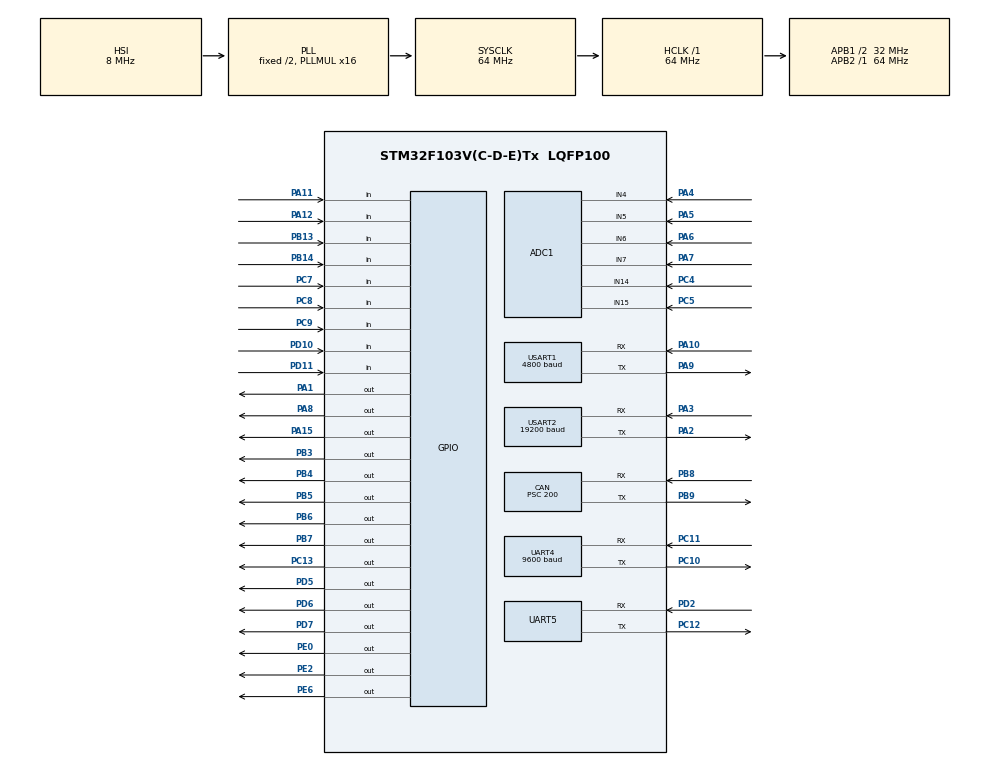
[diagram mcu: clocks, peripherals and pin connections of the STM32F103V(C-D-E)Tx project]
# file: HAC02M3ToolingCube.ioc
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ADC1.Channel-0\#ChannelRegularConversion=ADC_CHANNEL_4
ADC1.Channel-1\#ChannelRegularConversion=ADC_CHANNEL_5
ADC1.Channel-2\#ChannelRegularConversion=ADC_CHANNEL_6
ADC1.Channel-3\#ChannelRegularConversion=ADC_CHANNEL_7
ADC1.Channel-4\#ChannelRegularConversion=ADC_CHANNEL_14
ADC1.Channel-5\#ChannelRegularConversion=ADC_CHANNEL_15
ADC1.ContinuousConvMode=ENABLE
ADC1.NbrOfConversion=6
ADC1.NbrOfConversionFlag=1
ADC1.Rank-0\#ChannelRegularConversion=1
ADC1.Rank-1\#ChannelRegularConversion=2
ADC1.Rank-2\#ChannelRegularConversion=3
ADC1.Rank-3\#ChannelRegularConversion=4
ADC1.Rank-4\#ChannelRegularConversion=5
ADC1.Rank-5\#ChannelRegularConversion=6
ADC1.SamplingTime-0\#ChannelRegularConversion=ADC_SAMPLETIME_239CYCLES_5
ADC1.SamplingTime-1\#ChannelRegularConversion=ADC_SAMPLETIME_239CYCLES_5
ADC1.SamplingTime-2\#ChannelRegularConversion=ADC_SAMPLETIME_239CYCLES_5
ADC1.SamplingTime-3\#ChannelRegularConversion=ADC_SAMPLETIME_239CYCLES_5
ADC1.SamplingTime-4\#ChannelRegularConversion=ADC_SAMPLETIME_239CYCLES_5
ADC1.SamplingTime-5\#ChannelRegularConversion=ADC_SAMPLETIME_239CYCLES_5
ADC1.master=1
CAN.ABOM=DISABLE
CAN.BS1=CAN_BS1_3TQ
CAN.BS2=CAN_BS2_4TQ
CAN.CalculateBaudRate=20000
CAN.CalculateTimeBit=50000
CAN.CalculateTimeQuantum=6250.0
CAN.Prescaler=200
CAN.TTCM=DISABLE
CAN.TXFP=DISABLE
Dma.ADC1.0.Direction=DMA_PERIPH_TO_MEMORY
Dma.ADC1.0.Instance=DMA1_Channel1
Dma.ADC1.0.MemDataAlignment=DMA_MDATAALIGN_HALFWORD
Dma.ADC1.0.MemInc=DMA_MINC_ENABLE
Dma.ADC1.0.Mode=DMA_CIRCULAR
Dma.ADC1.0.PeriphDataAlignment=DMA_PDATAALIGN_HALFWORD
Dma.ADC1.0.PeriphInc=DMA_PINC_DISABLE
Dma.ADC1.0.Priority=DMA_PRIORITY_LOW
Dma.Request0=ADC1
Dma.Request1=USART1_RX
Dma.Request2=USART1_TX
Dma.Request3=USART2_RX
Dma.Request4=USART2_TX
Dma.Request5=UART4_RX
Dma.Request6=UART4_TX
Dma.UART4_RX.5.Direction=DMA_PERIPH_TO_MEMORY
Dma.UART4_RX.5.Instance=DMA2_Channel3
Dma.UART4_RX.5.MemDataAlignment=DMA_MDATAALIGN_BYTE
Dma.UART4_RX.5.MemInc=DMA_MINC_ENABLE
Dma.UART4_RX.5.Mode=DMA_NORMAL
Dma.UART4_RX.5.PeriphDataAlignment=DMA_PDATAALIGN_BYTE
Dma.UART4_RX.5.PeriphInc=DMA_PINC_DISABLE
Dma.UART4_RX.5.Priority=DMA_PRIORITY_LOW
Dma.UART4_TX.6.Direction=DMA_MEMORY_TO_PERIPH
Dma.UART4_TX.6.Instance=DMA2_Channel5
Dma.UART4_TX.6.MemDataAlignment=DMA_MDATAALIGN_BYTE
Dma.UART4_TX.6.MemInc=DMA_MINC_ENABLE
Dma.UART4_TX.6.Mode=DMA_NORMAL
Dma.UART4_TX.6.PeriphDataAlignment=DMA_PDATAALIGN_BYTE
Dma.UART4_TX.6.PeriphInc=DMA_PINC_DISABLE
Dma.UART4_TX.6.Priority=DMA_PRIORITY_LOW
Dma.USART1_RX.1.Direction=DMA_PERIPH_TO_MEMORY
Dma.USART1_RX.1.Instance=DMA1_Channel5
Dma.USART1_RX.1.MemDataAlignment=DMA_MDATAALIGN_BYTE
Dma.USART1_RX.1.MemInc=DMA_MINC_ENABLE
Dma.USART1_RX.1.Mode=DMA_NORMAL
Dma.USART1_RX.1.PeriphDataAlignment=DMA_PDATAALIGN_BYTE
Dma.USART1_RX.1.PeriphInc=DMA_PINC_DISABLE
Dma.USART1_RX.1.Priority=DMA_PRIORITY_LOW
Dma.USART1_TX.2.Direction=DMA_MEMORY_TO_PERIPH
Dma.USART1_TX.2.Instance=DMA1_Channel4
Dma.USART1_TX.2.MemDataAlignment=DMA_MDATAALIGN_BYTE
Dma.USART1_TX.2.MemInc=DMA_MINC_ENABLE
Dma.USART1_TX.2.Mode=DMA_NORMAL
Dma.USART1_TX.2.PeriphDataAlignment=DMA_PDATAALIGN_BYTE
Dma.USART1_TX.2.PeriphInc=DMA_PINC_DISABLE
Dma.USART1_TX.2.Priority=DMA_PRIORITY_LOW
Dma.USART2_RX.3.Direction=DMA_PERIPH_TO_MEMORY
Dma.USART2_RX.3.Instance=DMA1_Channel6
Dma.USART2_RX.3.MemDataAlignment=DMA_MDATAALIGN_BYTE
Dma.USART2_RX.3.MemInc=DMA_MINC_ENABLE
Dma.USART2_RX.3.Mode=DMA_NORMAL
Dma.USART2_RX.3.PeriphDataAlignment=DMA_PDATAALIGN_BYTE
Dma.USART2_RX.3.PeriphInc=DMA_PINC_DISABLE
Dma.USART2_RX.3.Priority=DMA_PRIORITY_LOW
Dma.USART2_TX.4.Direction=DMA_MEMORY_TO_PERIPH
Dma.USART2_TX.4.Instance=DMA1_Channel7
Dma.USART2_TX.4.MemDataAlignment=DMA_MDATAALIGN_BYTE
Dma.USART2_TX.4.MemInc=DMA_MINC_ENABLE
Dma.USART2_TX.4.Mode=DMA_NORMAL
Dma.USART2_TX.4.PeriphDataAlignment=DMA_PDATAALIGN_BYTE
Dma.USART2_TX.4.PeriphInc=DMA_PINC_DISABLE
Dma.USART2_TX.4.Priority=DMA_PRIORITY_LOW
IWDG.Prescaler=IWDG_PRESCALER_128
IWDG.Reload=800
Mcu.Family=STM32F1
Mcu.Name=STM32F103V(C-D-E)Tx
Mcu.Package=LQFP100
NVIC.DMA1_Channel1_IRQn=true\:0\:0\:false\:false\:true\:false\:true\:true
NVIC.DMA1_Channel4_IRQn=true\:0\:0\:false\:false\:true\:false\:true\:true
NVIC.DMA1_Channel5_IRQn=true\:0\:0\:false\:false\:true\:false\:true\:true
NVIC.DMA1_Channel6_IRQn=true\:0\:0\:false\:false\:true\:false\:true\:true
NVIC.DMA1_Channel7_IRQn=true\:0\:0\:false\:false\:true\:false\:true\:true
NVIC.DMA2_Channel3_IRQn=true\:0\:0\:false\:false\:true\:false\:true\:true
NVIC.DMA2_Channel4_5_IRQn=true\:0\:0\:false\:false\:true\:false\:true\:true
NVIC.PriorityGroup=NVIC_PRIORITYGROUP_4
NVIC.TIM2_IRQn=true\:15\:0\:true\:false\:true\:false\:true\:true
NVIC.TimeBase=TIM2_IRQn
NVIC.TimeBaseIP=TIM2
NVIC.UART4_IRQn=true\:0\:0\:false\:false\:true\:true\:true\:true
NVIC.UART5_IRQn=true\:0\:0\:false\:false\:true\:true\:true\:true
NVIC.USART1_IRQn=true\:0\:0\:false\:false\:true\:true\:true\:true
NVIC.USART2_IRQn=true\:0\:0\:false\:false\:true\:true\:true\:true
NVIC.USB_LP_CAN1_RX0_IRQn=true\:0\:0\:false\:false\:true\:true\:true\:true
PA1.Signal=GPIO_Output
PA10.Mode=Asynchronous
PA10.Signal=USART1_RX
PA11.Signal=GPIO_Input
PA12.Signal=GPIO_Input
PA13.Mode=Serial_Wire
PA13.Signal=SYS_JTMS-SWDIO
PA14.Mode=Serial_Wire
PA14.Signal=SYS_JTCK-SWCLK
PA15.Signal=GPIO_Output
PA2.Mode=Asynchronous
PA2.Signal=USART2_TX
PA3.Mode=Asynchronous
PA3.Signal=USART2_RX
PA4.Signal=ADCx_IN4
PA5.Signal=ADCx_IN5
PA6.Signal=ADCx_IN6
PA7.Signal=ADCx_IN7
PA8.Signal=GPIO_Output
PA9.Mode=Asynchronous
PA9.Signal=USART1_TX
PB13.Signal=GPIO_Input
PB14.Signal=GPIO_Input
PB3.Signal=GPIO_Output
PB4.Signal=GPIO_Output
PB5.Signal=GPIO_Output
PB6.Signal=GPIO_Output
PB7.Signal=GPIO_Output
PB8.Mode=CAN_Activate
PB8.Signal=CAN_RX
PB9.Mode=CAN_Activate
PB9.Signal=CAN_TX
PC10.Mode=Asynchronous
PC10.Signal=UART4_TX
PC11.Mode=Asynchronous
PC11.Signal=UART4_RX
PC12.Mode=Asynchronous
PC12.Signal=UART5_TX
PC13-TAMPER-RTC.Signal=GPIO_Output
PC4.Signal=ADCx_IN14
PC5.Signal=ADCx_IN15
PC7.Signal=GPIO_Input
PC8.Signal=GPIO_Input
PC9.Signal=GPIO_Input
PD10.Signal=GPIO_Input
PD11.Signal=GPIO_Input
PD2.Mode=Asynchronous
PD2.Signal=UART5_RX
PD5.Signal=GPIO_Output
PD6.Signal=GPIO_Output
PD7.Signal=GPIO_Output
PE0.Signal=GPIO_Output
PE2.Signal=GPIO_Output
PE6.Signal=GPIO_Output
ProjectManager.HeapSize=0x200
ProjectManager.StackSize=0x400
ProjectManager.TargetToolchain=MDK-ARM V5.32
RCC.ADCPresc=RCC_ADCPCLK2_DIV6
RCC.AHBFreq_Value=64000000
RCC.APB1CLKDivider=RCC_HCLK_DIV2
RCC.APB1Freq_Value=32000000
RCC.APB1TimFreq_Value=64000000
RCC.APB2Freq_Value=64000000
RCC.APB2TimFreq_Value=64000000
RCC.HCLKFreq_Value=64000000
RCC.PLLMUL=RCC_PLL_MUL16
RCC.SYSCLKFreq_VALUE=64000000
RCC.SYSCLKSource=RCC_SYSCLKSOURCE_PLLCLK
RCC.USBFreq_Value=64000000
SH.ADCx_IN14.0=ADC1_IN14,IN14
SH.ADCx_IN15.0=ADC1_IN15,IN15
SH.ADCx_IN4.0=ADC1_IN4,IN4
SH.ADCx_IN5.0=ADC1_IN5,IN5
SH.ADCx_IN6.0=ADC1_IN6,IN6
SH.ADCx_IN7.0=ADC1_IN7,IN7
UART4.BaudRate=9600
UART4.VirtualMode=Asynchronous
UART5.VirtualMode=Asynchronous
USART1.BaudRate=4800
USART1.VirtualMode=VM_ASYNC
USART2.BaudRate=19200
USART2.VirtualMode=VM_ASYNC
VP_IWDG_VS_IWDG.Mode=IWDG_Activate
VP_SYS_VS_tim2.Mode=TIM2
board=custom

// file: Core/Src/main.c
/* USER CODE BEGIN Header */
/**
  ******************************************************************************
  * @file           : main.c
  * @brief          : Main program body
  ******************************************************************************
  * @attention
  *
  * Copyright (c) 2022 STMicroelectronics.
  * All rights reserved.
  *
  * This software is licensed under terms that can be found in the LICENSE file
  * in the root directory of this software component.
  * If no LICENSE file comes with this software, it is provided AS-IS.
  *
  ******************************************************************************
  */
/* USER CODE END Header */
#include "main.h"
#include "adc.h"
#include "can.h"
#include "dma.h"
#include "iwdg.h"
#include "usart.h"
#include "gpio.h"

/* USER CODE BEGIN Includes */

#define osObjectsPublic  // define objects in main module
#include "osObjects.h"   // RTOS object definitions

/* USER CODE END Includes */

void SystemClock_Config(void);

int main(void)
{

  /* MCU Configuration--------------------------------------------------------*/

  /* Reset of all peripherals, Initializes the Flash interface and the Systick. */
  HAL_Init();

  /* Configure the system clock */
  SystemClock_Config();

  /* Initialize all configured peripherals */
  MX_GPIO_Init();
  MX_DMA_Init();
  MX_USART2_UART_Init();
  MX_ADC1_Init();
  MX_IWDG_Init();
  MX_CAN_Init();
  MX_USART1_UART_Init();
  MX_UART4_Init();
  MX_UART5_Init();
  /* USER CODE BEGIN 2 */
  Init_Thread();
  Init_testThread();
  /* USER CODE END 2 */

  /* Infinite loop */
  while (1)
  {

    /* USER CODE BEGIN 3 */
        osDelay(500);
        HAL_GPIO_TogglePin(GPIOC, GPIO_PIN_13);
        HAL_IWDG_Refresh(&hiwdg);
    }
  /* USER CODE END 3 */
}

void SystemClock_Config(void)
{
  RCC_OscInitTypeDef RCC_OscInitStruct = {0};
  RCC_ClkInitTypeDef RCC_ClkInitStruct = {0};
  RCC_PeriphCLKInitTypeDef PeriphClkInit = {0};

  /** Initializes the RCC Oscillators according to the specified parameters
  * in the RCC_OscInitTypeDef structure.
  */
  RCC_OscInitStruct.OscillatorType = RCC_OSCILLATORTYPE_HSI|RCC_OSCILLATORTYPE_LSI;
  RCC_OscInitStruct.HSIState = RCC_HSI_ON;
  RCC_OscInitStruct.HSICalibrationValue = RCC_HSICALIBRATION_DEFAULT;
  RCC_OscInitStruct.LSIState = RCC_LSI_ON;
  RCC_OscInitStruct.PLL.PLLState = RCC_PLL_ON;
  RCC_OscInitStruct.PLL.PLLSource = RCC_PLLSOURCE_HSI_DIV2;
  RCC_OscInitStruct.PLL.PLLMUL = RCC_PLL_MUL16;
  if (HAL_RCC_OscConfig(&RCC_OscInitStruct) != HAL_OK)
  {
    Error_Handler();
  }

  /** Initializes the CPU, AHB and APB buses clocks
  */
  RCC_ClkInitStruct.ClockType = RCC_CLOCKTYPE_HCLK|RCC_CLOCKTYPE_SYSCLK
                              |RCC_CLOCKTYPE_PCLK1|RCC_CLOCKTYPE_PCLK2;
  RCC_ClkInitStruct.SYSCLKSource = RCC_SYSCLKSOURCE_PLLCLK;
  RCC_ClkInitStruct.AHBCLKDivider = RCC_SYSCLK_DIV1;
  RCC_ClkInitStruct.APB1CLKDivider = RCC_HCLK_DIV2;
  RCC_ClkInitStruct.APB2CLKDivider = RCC_HCLK_DIV1;

  if (HAL_RCC_ClockConfig(&RCC_ClkInitStruct, FLASH_LATENCY_2) != HAL_OK)
  {
    Error_Handler();
  }
  PeriphClkInit.PeriphClockSelection = RCC_PERIPHCLK_ADC;
  PeriphClkInit.AdcClockSelection = RCC_ADCPCLK2_DIV6;
  if (HAL_RCCEx_PeriphCLKConfig(&PeriphClkInit) != HAL_OK)
  {
    Error_Handler();
  }
}

void HAL_TIM_PeriodElapsedCallback(TIM_HandleTypeDef *htim)
{
  if (htim->Instance == TIM2) {
    HAL_IncTick();
  }
}

void Error_Handler(void)
{
  __disable_irq();
  while (1)
  {
  }
}
